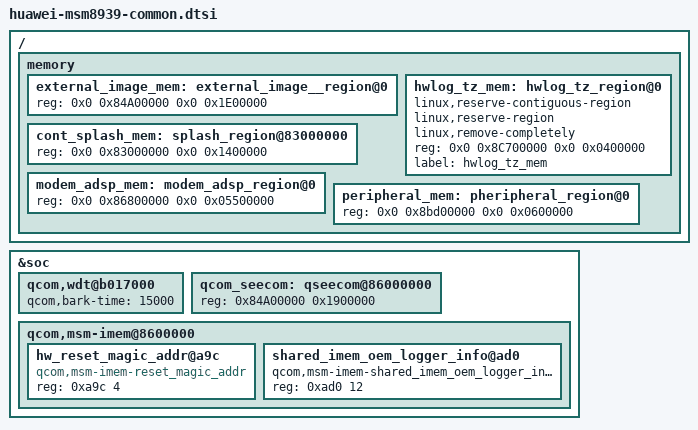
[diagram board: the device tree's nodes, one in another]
/ {
	memory {
		external_image_mem: external_image__region@0 {
			reg = <0x0 0x84A00000 0x0 0x1E00000>;
	};

		hwlog_tz_mem: hwlog_tz_region@0 {
			linux,reserve-contiguous-region;
			linux,reserve-region;
			linux,remove-completely;
			reg = <0x0 0x8C700000 0x0 0x0400000>;
			label = "hwlog_tz_mem";
		};

		cont_splash_mem: splash_region@83000000 {
			reg = <0x0 0x83000000 0x0 0x1400000>;
		};

		modem_adsp_mem: modem_adsp_region@0 {
			reg = <0x0 0x86800000 0x0 0x05500000>;
		};

		peripheral_mem: pheripheral_region@0 {
			reg = <0x0 0x8bd00000 0x0 0x0600000>;
		};

	};
};

&soc {
	qcom,wdt@b017000 {
		qcom,bark-time = <15000>;
	};

	qcom_seecom: qseecom@86000000 {
		reg = <0x84A00000 0x1900000>;
	};

	qcom,msm-imem@8600000 {
		hw_reset_magic_addr@a9c {
			compatible = "qcom,msm-imem-reset_magic_addr";
			reg = <0xa9c 4>;
		};

		shared_imem_oem_logger_info@ad0 {
			compatible = "qcom,msm-imem-shared_imem_oem_logger_info";
			reg = <0xad0 12>;
		};

	/delete-node/ dma_blsp1;

	};
};
